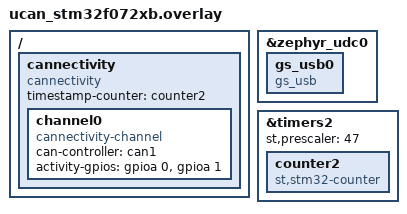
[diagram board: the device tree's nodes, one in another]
/*
 * Copyright (c) 2024 Henrik Brix Andersen <henrik@brixandersen.dk>
 *
 * SPDX-License-Identifier: Apache-2.0
 */

#include <zephyr/dt-bindings/gpio/gpio.h>

/ {
	cannectivity: cannectivity {
		compatible = "cannectivity";
		timestamp-counter = <&counter2>;

		channel0 {
			compatible = "cannectivity-channel";
			can-controller = <&can1>;
			activity-gpios = <&gpioa 0 GPIO_ACTIVE_HIGH>,
					 <&gpioa 1 GPIO_ACTIVE_HIGH>;
		};
	};
};

&zephyr_udc0 {
	gs_usb0: gs_usb0 {
		compatible = "gs_usb";
	};
};

&timers2 {
	status = "okay";
	st,prescaler = <47>;

	counter2: counter2 {
		compatible = "st,stm32-counter";
		status = "okay";
	};
};
